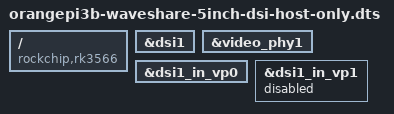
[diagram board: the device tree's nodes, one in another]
/dts-v1/;
/plugin/;

/ {
	compatible = "rockchip,rk3566";

	fragment@0 {
		target = <&dsi1>;
		__overlay__ {
			status = "okay";
		};
	};

	fragment@1 {
		target = <&video_phy1>;
		__overlay__ {
			status = "okay";
		};
	};

	fragment@2 {
		target = <&dsi1_in_vp0>;
		__overlay__ {
			status = "okay";
		};
	};

	fragment@3 {
		target = <&dsi1_in_vp1>;
		__overlay__ {
			status = "disabled";
		};
	};
};
